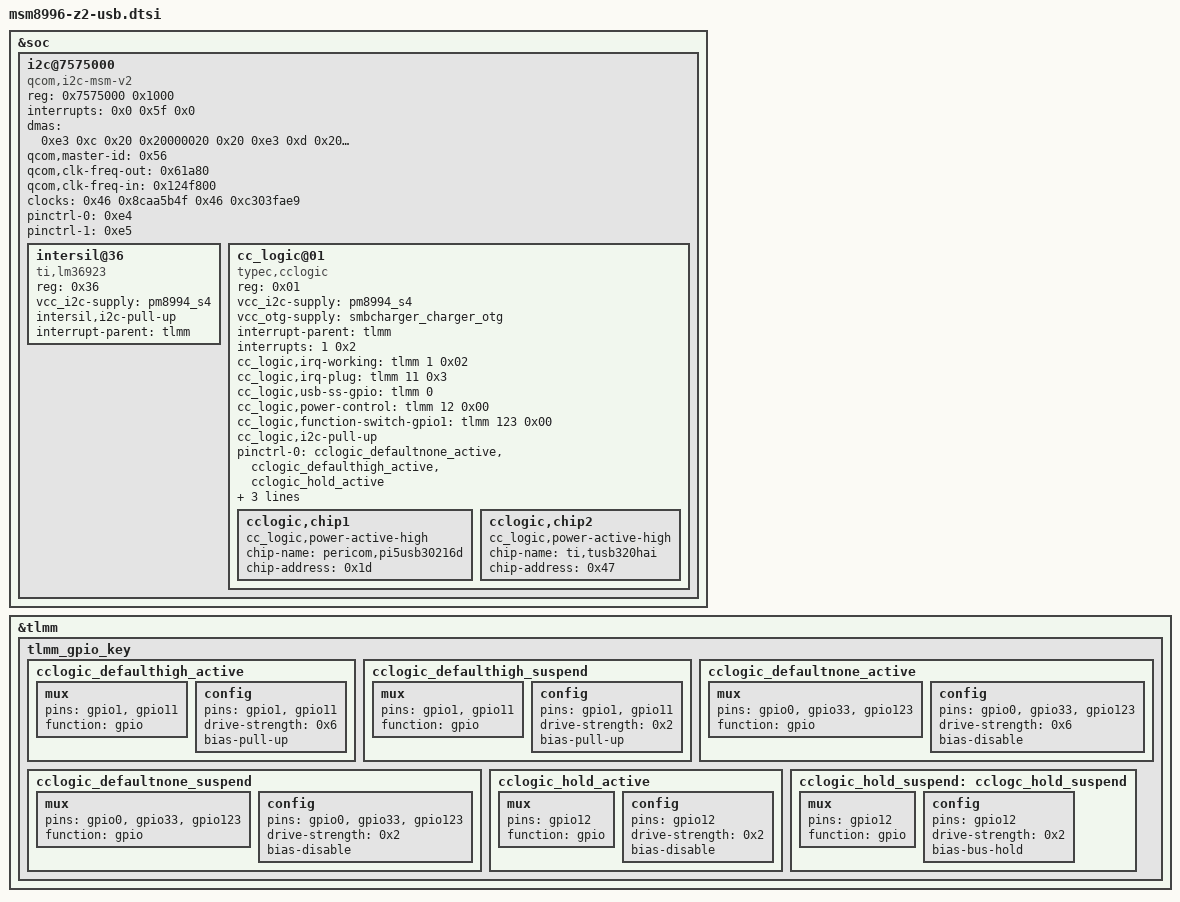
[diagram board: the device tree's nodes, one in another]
&soc {
	i2c@7575000 {
		compatible = "qcom,i2c-msm-v2";
		#address-cells = <0x1>;
		#size-cells = <0x0>;
		reg-names = "qup_phys_addr";
		reg = <0x7575000 0x1000>;
		interrupt-names = "qup_irq";
		interrupts = <0x0 0x5f 0x0>;
		dmas = <0xe3 0xc 0x20 0x20000020 0x20 0xe3 0xd 0x20 0x20000020 0x20>;
		dma-names = "tx", "rx";
		qcom,master-id = <0x56>;
		qcom,clk-freq-out = <0x61a80>;
		qcom,clk-freq-in = <0x124f800>;
		clock-names = "iface_clk", "core_clk";
		clocks = <0x46 0x8caa5b4f 0x46 0xc303fae9>;
		pinctrl-names = "i2c_active", "i2c_sleep";
		pinctrl-0 = <0xe4>;
		pinctrl-1 = <0xe5>;
		intersil@36 {
			compatible = "ti,lm36923";
			reg = <0x36>;
			vcc_i2c-supply = <&pm8994_s4>;
			intersil,i2c-pull-up;
			interrupt-parent = <&tlmm>;
		};
		cc_logic@01 {
			compatible = "typec,cclogic";
			reg = <0x01>;
			vcc_i2c-supply = <&pm8994_s4>;
			vcc_otg-supply = <&smbcharger_charger_otg>;/* use for otg power */
			interrupt-parent = <&tlmm>;
			interrupts = <1 0x2>;

			cc_logic,irq-working = <&tlmm 1 0x02>; //for 0x8 low_level interrupt, 0x2 falling_edge
			cc_logic,irq-plug = <&tlmm 11 0x3>;//for both edge
			cc_logic,usb-ss-gpio = <&tlmm 0 0x00>;
			cc_logic,power-control = <&tlmm 12 0x00>;
			cc_logic,function-switch-gpio1 = <&tlmm 123 0x00>;
			cc_logic,i2c-pull-up;
			pinctrl-names = "cc_active", "cc_sleep";
			pinctrl-0 = <&cclogic_defaultnone_active &cclogic_defaulthigh_active &cclogic_hold_active>;
			pinctrl-1 = <&cclogic_defaultnone_suspend &cclogic_defaulthigh_suspend &cclogic_hold_suspend>;
			cclogic,chip1 {
				cc_logic,power-active-high;
				chip-name = "pericom,pi5usb30216d";
				chip-address = <0x1d>;
			};
			cclogic,chip2 {
				cc_logic,power-active-high;
				chip-name = "ti,tusb320hai";
				chip-address = <0x47>;
			};
		};
	};
};

&tlmm {
	tlmm_gpio_key {
		cclogic_defaulthigh_active: cclogic_defaulthigh_active {
			mux {
				pins = "gpio1", "gpio11";
				function = "gpio";
			};
			config {
				pins = "gpio1", "gpio11";
				drive-strength = <0x6>;
				bias-pull-up;
			};
		};
		cclogic_defaulthigh_suspend: cclogic_defaulthigh_suspend {
			mux {
				pins = "gpio1", "gpio11";
				function = "gpio";
			};
			config {
				pins = "gpio1", "gpio11";
				drive-strength = <0x2>;
				bias-pull-up;
			};
		};
		cclogic_defaultnone_active: cclogic_defaultnone_active {
			mux {
				pins = "gpio0", "gpio33", "gpio123";
				function = "gpio";
			};
			config {
				pins = "gpio0", "gpio33", "gpio123";
				drive-strength = <0x6>;
				bias-disable;
			};
		};
		cclogic_defaultnone_suspend: cclogic_defaultnone_suspend {
			mux {
				pins = "gpio0", "gpio33", "gpio123";
				function = "gpio";
			};
			config {
				pins = "gpio0", "gpio33", "gpio123";
				drive-strength = <0x2>;
				bias-disable;
			};
		};
		cclogic_hold_active: cclogic_hold_active {
			mux {
				pins = "gpio12";
				function = "gpio";
			};
			config {
				pins = "gpio12";
				drive-strength = <0x2>;
				bias-disable;
			};
		};
		cclogic_hold_suspend: cclogc_hold_suspend {
			mux {
				pins = "gpio12";
				function = "gpio";
			};
			config {
				pins = "gpio12";
				drive-strength = <0x2>;
				bias-bus-hold;
			};
		};
	};
};
